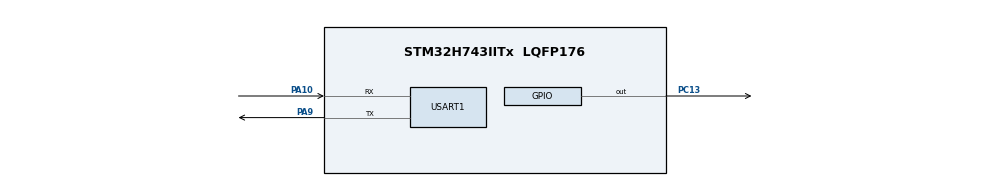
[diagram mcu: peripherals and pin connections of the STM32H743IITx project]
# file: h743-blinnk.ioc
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CORTEX_M7.default_mode_Activation=1
Mcu.Family=STM32H7
Mcu.Name=STM32H743IITx
Mcu.Package=LQFP176
NVIC.PriorityGroup=NVIC_PRIORITYGROUP_4
NVIC.TIM3_IRQn=true\:0\:0\:false\:false\:true\:true\:true\:true
NVIC.USART1_IRQn=true\:0\:0\:false\:false\:true\:true\:true\:true
PA10.Mode=Asynchronous
PA10.Signal=USART1_RX
PA9.Mode=Asynchronous
PA9.Signal=USART1_TX
PC13.Signal=GPIO_Output
ProjectManager.HeapSize=0x200
ProjectManager.StackSize=0x400
ProjectManager.TargetToolchain=STM32CubeIDE
RCC.ADCFreq_Value=129000000
RCC.APB1Freq_Value=64000000
RCC.APB2Freq_Value=32000000
RCC.APB3Freq_Value=64000000
RCC.APB4Freq_Value=64000000
RCC.CortexFreq_Value=64000000
RCC.D2PPRE2=RCC_APB2_DIV2
RCC.HCLKFreq_Value=64000000
RCC.LPUART1CLockSelection=RCC_LPUART1CLKSOURCE_HSI
RCC.SYSCLKFreq_VALUE=64000000
RCC.USBFreq_Value=129000000
TIM3.AutoReloadPreload=TIM_AUTORELOAD_PRELOAD_ENABLE
TIM3.Period=999
TIM3.Prescaler=63
USART1.VirtualMode-Asynchronous=VM_ASYNC
VP_MEMORYMAP_VS_MEMORYMAP.Mode=CurAppReg
VP_TIM3_VS_ClockSourceINT.Mode=Internal
board=custom

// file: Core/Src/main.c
/* USER CODE BEGIN Header */
/**
  ******************************************************************************
  * @file           : main.c
  * @brief          : Main program body
  ******************************************************************************
  * @attention
  *
  * Copyright (c) 2026 STMicroelectronics.
  * All rights reserved.
  *
  * This software is licensed under terms that can be found in the LICENSE file
  * in the root directory of this software component.
  * If no LICENSE file comes with this software, it is provided AS-IS.
  *
  ******************************************************************************
  */
/* USER CODE END Header */
#include "main.h"

TIM_HandleTypeDef htim3;

UART_HandleTypeDef huart1;

/* USER CODE BEGIN PV */
uint16_t LEDcounter= 0;
uint16_t UARTcounter= 0;
uint32_t number= 0;
uint16_t transmitData= 0;
uint16_t uartBusy= 0;
char msg[32];
/* USER CODE END PV */

void SystemClock_Config(void);
static void MPU_Config(void);
static void MX_GPIO_Init(void);
static void MX_TIM3_Init(void);
static void MX_USART1_UART_Init(void);

int main(void)
{

  /* MPU Configuration--------------------------------------------------------*/
  MPU_Config();

  /* MCU Configuration--------------------------------------------------------*/

  /* Reset of all peripherals, Initializes the Flash interface and the Systick. */
  HAL_Init();

  /* Configure the system clock */
  SystemClock_Config();

  /* Initialize all configured peripherals */
  MX_GPIO_Init();
  MX_TIM3_Init();
  MX_USART1_UART_Init();

  /* Infinite loop */
  while (1)
  {

    /* USER CODE BEGIN 3 */
	  if (!uartBusy && transmitData == 1)
	  {
	      uartBusy = 1;
	      transmitData= 0;
	      snprintf(msg, "%lu\r\n", number++);
	      HAL_UART_Transmit_IT(&huart1, (uint8_t*)msg, strlen(msg));
	  }
  }
  /* USER CODE END 3 */
}

void SystemClock_Config(void)
{
  RCC_OscInitTypeDef RCC_OscInitStruct = {0};
  RCC_ClkInitTypeDef RCC_ClkInitStruct = {0};

  /** Supply configuration update enable
  */
  HAL_PWREx_ConfigSupply(PWR_LDO_SUPPLY);

  /** Configure the main internal regulator output voltage
  */
  __HAL_PWR_VOLTAGESCALING_CONFIG(PWR_REGULATOR_VOLTAGE_SCALE3);

  while(!__HAL_PWR_GET_FLAG(PWR_FLAG_VOSRDY)) {}

  /** Initializes the RCC Oscillators according to the specified parameters
  * in the RCC_OscInitTypeDef structure.
  */
  RCC_OscInitStruct.OscillatorType = RCC_OSCILLATORTYPE_HSI;
  RCC_OscInitStruct.HSIState = RCC_HSI_DIV1;
  RCC_OscInitStruct.HSICalibrationValue = RCC_HSICALIBRATION_DEFAULT;
  RCC_OscInitStruct.PLL.PLLState = RCC_PLL_NONE;
  if (HAL_RCC_OscConfig(&RCC_OscInitStruct) != HAL_OK)
  {
    Error_Handler();
  }

  /** Initializes the CPU, AHB and APB buses clocks
  */
  RCC_ClkInitStruct.ClockType = RCC_CLOCKTYPE_HCLK|RCC_CLOCKTYPE_SYSCLK
                              |RCC_CLOCKTYPE_PCLK1|RCC_CLOCKTYPE_PCLK2
                              |RCC_CLOCKTYPE_D3PCLK1|RCC_CLOCKTYPE_D1PCLK1;
  RCC_ClkInitStruct.SYSCLKSource = RCC_SYSCLKSOURCE_HSI;
  RCC_ClkInitStruct.SYSCLKDivider = RCC_SYSCLK_DIV1;
  RCC_ClkInitStruct.AHBCLKDivider = RCC_HCLK_DIV1;
  RCC_ClkInitStruct.APB3CLKDivider = RCC_APB3_DIV1;
  RCC_ClkInitStruct.APB1CLKDivider = RCC_APB1_DIV1;
  RCC_ClkInitStruct.APB2CLKDivider = RCC_APB2_DIV2;
  RCC_ClkInitStruct.APB4CLKDivider = RCC_APB4_DIV1;

  if (HAL_RCC_ClockConfig(&RCC_ClkInitStruct, FLASH_LATENCY_1) != HAL_OK)
  {
    Error_Handler();
  }
}

static void MX_TIM3_Init(void)
{

  /* USER CODE BEGIN TIM3_Init 0 */
  HAL_NVIC_SetPriority(TIM3_IRQn, 1, 0);
  HAL_NVIC_EnableIRQ(TIM3_IRQn);
  /* USER CODE END TIM3_Init 0 */

  TIM_ClockConfigTypeDef sClockSourceConfig = {0};
  TIM_MasterConfigTypeDef sMasterConfig = {0};

  htim3.Instance = TIM3;
  htim3.Init.Prescaler = 63;
  htim3.Init.CounterMode = TIM_COUNTERMODE_UP;
  htim3.Init.Period = 999;
  htim3.Init.ClockDivision = TIM_CLOCKDIVISION_DIV1;
  htim3.Init.AutoReloadPreload = TIM_AUTORELOAD_PRELOAD_ENABLE;
  if (HAL_TIM_Base_Init(&htim3) != HAL_OK)
  {
    Error_Handler();
  }
  sClockSourceConfig.ClockSource = TIM_CLOCKSOURCE_INTERNAL;
  if (HAL_TIM_ConfigClockSource(&htim3, &sClockSourceConfig) != HAL_OK)
  {
    Error_Handler();
  }
  sMasterConfig.MasterOutputTrigger = TIM_TRGO_RESET;
  sMasterConfig.MasterSlaveMode = TIM_MASTERSLAVEMODE_DISABLE;
  if (HAL_TIMEx_MasterConfigSynchronization(&htim3, &sMasterConfig) != HAL_OK)
  {
    Error_Handler();
  }
  /* USER CODE BEGIN TIM3_Init 2 */
  HAL_TIM_Base_Start_IT(&htim3);
  /* USER CODE END TIM3_Init 2 */

}

static void MX_USART1_UART_Init(void)
{

  huart1.Instance = USART1;
  huart1.Init.BaudRate = 115200;
  huart1.Init.WordLength = UART_WORDLENGTH_8B;
  huart1.Init.StopBits = UART_STOPBITS_1;
  huart1.Init.Parity = UART_PARITY_NONE;
  huart1.Init.Mode = UART_MODE_TX_RX;
  huart1.Init.HwFlowCtl = UART_HWCONTROL_NONE;
  huart1.Init.OverSampling = UART_OVERSAMPLING_16;
  huart1.Init.OneBitSampling = UART_ONE_BIT_SAMPLE_DISABLE;
  huart1.Init.ClockPrescaler = UART_PRESCALER_DIV1;
  huart1.AdvancedInit.AdvFeatureInit = UART_ADVFEATURE_NO_INIT;
  if (HAL_UART_Init(&huart1) != HAL_OK)
  {
    Error_Handler();
  }
  if (HAL_UARTEx_SetTxFifoThreshold(&huart1, UART_TXFIFO_THRESHOLD_1_8) != HAL_OK)
  {
    Error_Handler();
  }
  if (HAL_UARTEx_SetRxFifoThreshold(&huart1, UART_RXFIFO_THRESHOLD_1_8) != HAL_OK)
  {
    Error_Handler();
  }
  if (HAL_UARTEx_DisableFifoMode(&huart1) != HAL_OK)
  {
    Error_Handler();
  }

}

static void MX_GPIO_Init(void)
{
  GPIO_InitTypeDef GPIO_InitStruct = {0};

  /* GPIO Ports Clock Enable */
  __HAL_RCC_GPIOC_CLK_ENABLE();
  __HAL_RCC_GPIOA_CLK_ENABLE();

  /*Configure GPIO pin Output Level */
  HAL_GPIO_WritePin(GPIOC, GPIO_PIN_13, GPIO_PIN_RESET);

  /*Configure GPIO pin : PC13 */
  GPIO_InitStruct.Pin = GPIO_PIN_13;
  GPIO_InitStruct.Mode = GPIO_MODE_OUTPUT_PP;
  GPIO_InitStruct.Pull = GPIO_NOPULL;
  GPIO_InitStruct.Speed = GPIO_SPEED_FREQ_LOW;
  HAL_GPIO_Init(GPIOC, &GPIO_InitStruct);

}

/* USER CODE BEGIN 4 */

void HAL_TIM_PeriodElapsedCallback(TIM_HandleTypeDef *htim)
{
    if (htim->Instance == TIM3)
    {
    	LEDcounter++;
    	UARTcounter++;
        if(LEDcounter <= 200){
        	HAL_GPIO_WritePin(GPIOC, GPIO_PIN_13, GPIO_PIN_SET);
        }else if(LEDcounter <= 400){
        	HAL_GPIO_WritePin(GPIOC, GPIO_PIN_13, GPIO_PIN_RESET);
        }else{
        	LEDcounter= 0;
        }
        if(UARTcounter >= 2000){
        	UARTcounter= 0;
        	transmitData= 1;
        }
    }
}
void HAL_UART_TxCpltCallback(UART_HandleTypeDef *huart)
{
    if (huart->Instance == USART1)
    {
        // Transmission finished
        // You can set a flag here if needed
    	uartBusy = 0;
    }
}
/* USER CODE END 4 */

 /* MPU Configuration */

void MPU_Config(void)
{
  MPU_Region_InitTypeDef MPU_InitStruct = {0};

  /* Disables the MPU */
  HAL_MPU_Disable();

  /** Initializes and configures the Region and the memory to be protected
  */
  MPU_InitStruct.Enable = MPU_REGION_ENABLE;
  MPU_InitStruct.Number = MPU_REGION_NUMBER0;
  MPU_InitStruct.BaseAddress = 0x0;
  MPU_InitStruct.Size = MPU_REGION_SIZE_4GB;
  MPU_InitStruct.SubRegionDisable = 0x87;
  MPU_InitStruct.TypeExtField = MPU_TEX_LEVEL0;
  MPU_InitStruct.AccessPermission = MPU_REGION_NO_ACCESS;
  MPU_InitStruct.DisableExec = MPU_INSTRUCTION_ACCESS_DISABLE;
  MPU_InitStruct.IsShareable = MPU_ACCESS_SHAREABLE;
  MPU_InitStruct.IsCacheable = MPU_ACCESS_NOT_CACHEABLE;
  MPU_InitStruct.IsBufferable = MPU_ACCESS_NOT_BUFFERABLE;

  HAL_MPU_ConfigRegion(&MPU_InitStruct);
  /* Enables the MPU */
  HAL_MPU_Enable(MPU_PRIVILEGED_DEFAULT);

}

void Error_Handler(void)
{
  __disable_irq();
  while (1)
  {
  }
}
